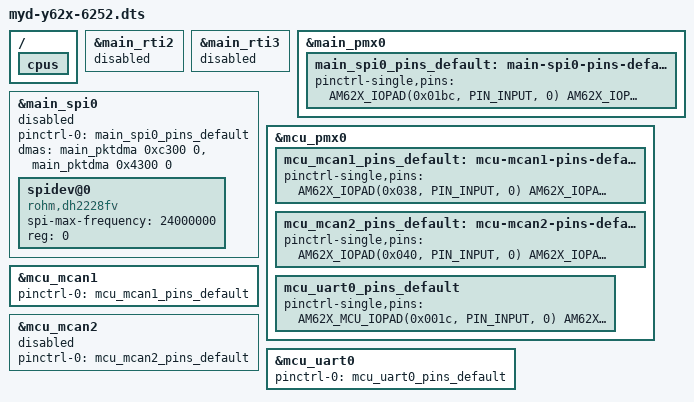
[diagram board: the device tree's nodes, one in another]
// SPDX-License-Identifier: GPL-2.0
/*
 * AM625 SK: https://www.ti.com/lit/zip/sprr448
 *
 * Copyright (C) 2021-2022 Texas Instruments Incorporated - https://www.ti.com/
 */

/dts-v1/;

#include <dt-bindings/leds/common.h>
#include <dt-bindings/gpio/gpio.h>
#include <dt-bindings/net/ti-dp83867.h>
#include "myd-y62x-common.dtsi"

/ {
//6252 shut down two watchdog
	cpus {
		/delete-node/ cpu-map;
		/delete-node/ cpu@2;
		/delete-node/ cpu@3;
	};
	// dma_buf_phys {
	// 	compatible = "ti,dma_buf_phys";
	// };
	
};
&main_rti2{
	status = "disabled";
};

&main_rti3{
	status = "disabled";
};
&main_pmx0 {
	main_spi0_pins_default: main-spi0-pins-default {
		pinctrl-single,pins = <
			AM62X_IOPAD(0x01bc, PIN_INPUT, 0) /* (A14) SPI0_CLK */
			AM62X_IOPAD(0x01c0, PIN_INPUT, 0) /* (B13) SPI0_D0 */
			AM62X_IOPAD(0x01c4, PIN_INPUT, 0) /* (B14) SPI0_D1 */
			AM62X_IOPAD(0x01b4, PIN_INPUT, 0) /* (A13) SPI0_CS0 */
		>;
	};
};
&main_spi0 {
	// status = "okay";
	status = "disabled";
	#address-cells = <1>;
	#size-cells = <0>;
	pinctrl-0 = <&main_spi0_pins_default>;
	pinctrl-names = "default";
    dmas = <&main_pktdma 0xc300 0>, <&main_pktdma 0x4300 0>;
    dma-names = "tx0", "rx0";
	spidev@0 {
		/*
		 * Using spidev compatible is warned loudly,
		 * thus use another equivalent compatible id
		 * from spidev.
		 */
		compatible = "rohm,dh2228fv";
		spi-max-frequency = <24000000>;
		reg = <0>;
	};
};

&mcu_pmx0 {
	mcu_mcan1_pins_default: mcu-mcan1-pins-default {
		pinctrl-single,pins = <
			AM62X_IOPAD(0x038, PIN_INPUT, 0) /* (B3) MCU_MCAN0_RX */
			AM62X_IOPAD(0x034, PIN_OUTPUT, 0) /* (D6) MCU_MCAN0_TX */
		>;
	};
	mcu_mcan2_pins_default: mcu-mcan2-pins-default {
		pinctrl-single,pins = <
			AM62X_IOPAD(0x040, PIN_INPUT, 0) /* (D4) MCU_MCAN1_RX */
			AM62X_IOPAD(0x03C, PIN_OUTPUT, 0) /* (E5) MCU_MCAN1_TX */
		>;
	};
	mcu_uart0_pins_default: mcu_uart0_pins_default {
		pinctrl-single,pins = <
            AM62X_MCU_IOPAD(0x001c, PIN_INPUT, 0) /* MCU_UART0_CTSn */
            AM62X_MCU_IOPAD(0x0020, PIN_OUTPUT, 0) /* MCU_UART0_RTSn */
            AM62X_MCU_IOPAD(0x0018, PIN_OUTPUT, 0) /* MCU_UART0_TXD */
        >;
	};
};
&mcu_mcan1 {
	pinctrl-names = "default";
	pinctrl-0 = <&mcu_mcan1_pins_default>;
	status = "okay";
	// status = "disabled";
};
&mcu_mcan2 {
	pinctrl-names = "default";
	pinctrl-0 = <&mcu_mcan2_pins_default>;
	// status = "okay";
	status = "disabled";
};
//开mcan2需要关mcu_gpio0里面的引脚复用
// &mcu_gpio0 {
// 	status = "disabled";
// };

&mcu_uart0 {
	status = "okay";
	pinctrl-names = "default";
	pinctrl-0 = <&mcu_uart0_pins_default>;
};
